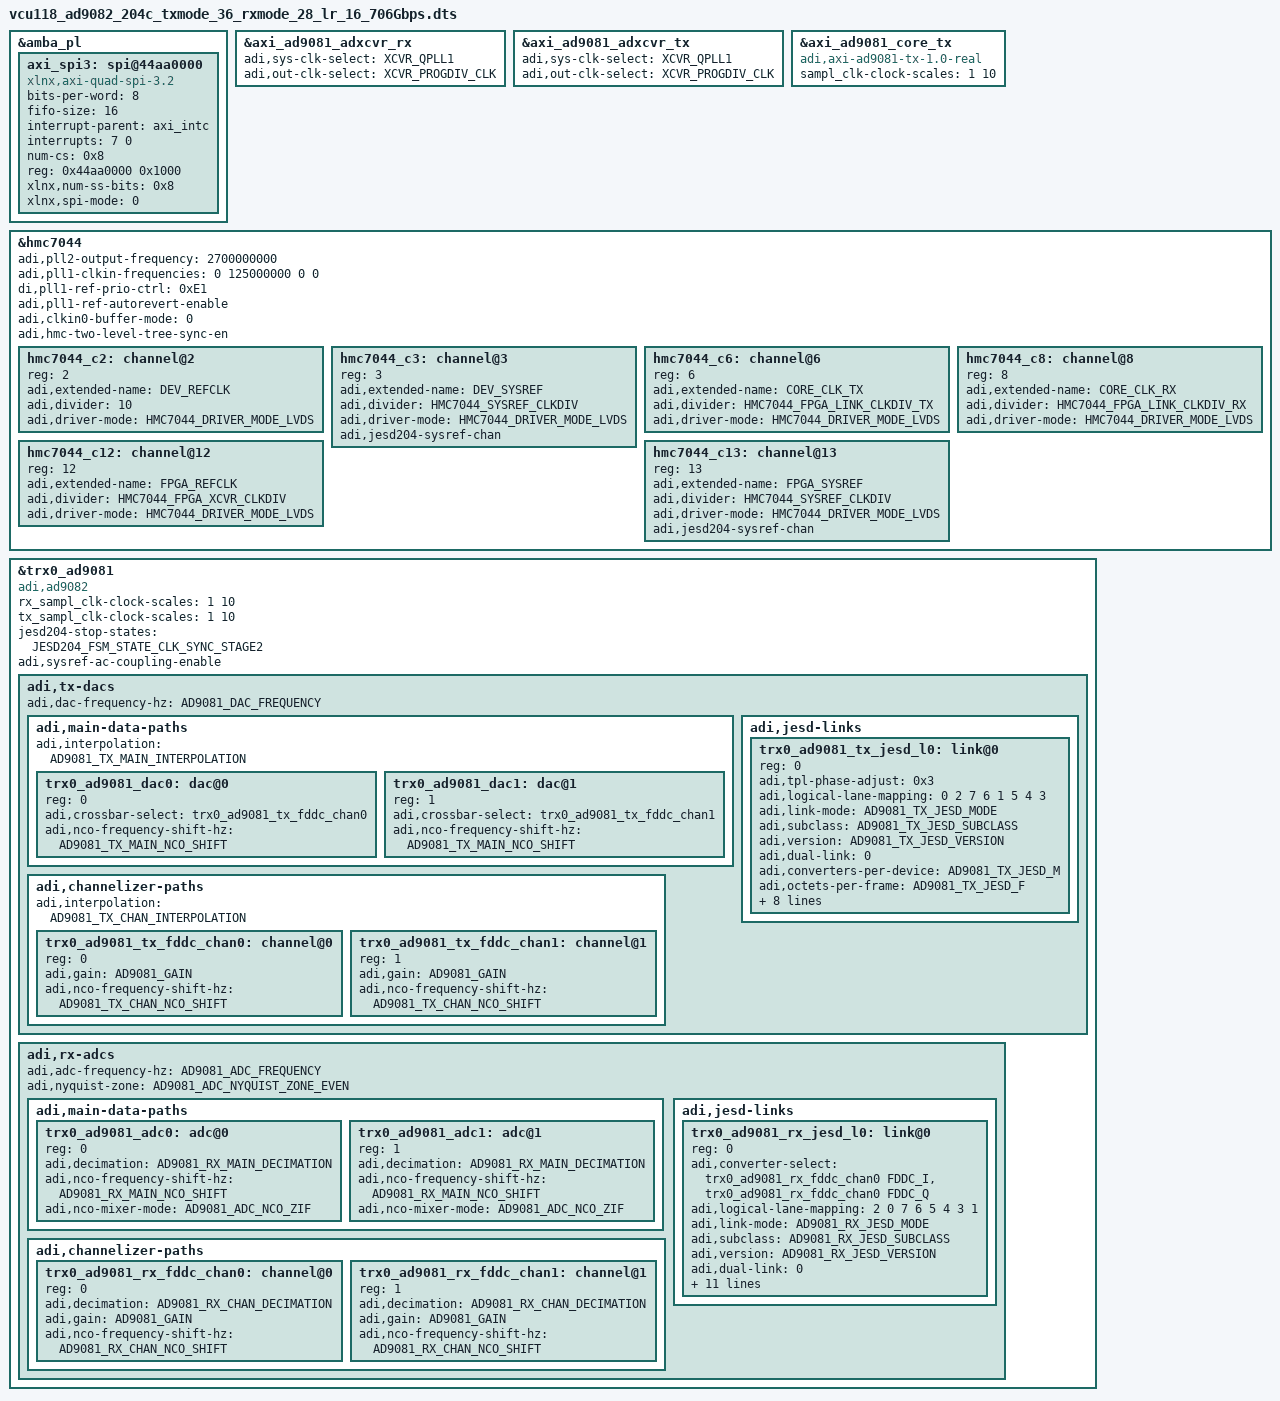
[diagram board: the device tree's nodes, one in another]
// SPDX-License-Identifier: GPL-2.0
/*
 * Analog Devices AD9082-FMC-EBZ
 * https://wiki.analog.com/resources/tools-software/linux-drivers/iio-mxfe/ad9081
 * https://wiki.analog.com/resources/eval/user-guides/ad9081_fmca_ebz/ad9081_fmca_ebz_hdl
 *
 * hdl_project: <ad9081_fmca_ebz/vcu118>
 * board_revision: <>
 *
 * Copyright (C) 2022 Analog Devices Inc.
 */

#include "vcu118_ad9081.dts"
#include <dt-bindings/jesd204/device-states.h>

#define HMC7044_FPGA_XCVR_CLKDIV		16
#define HMC7044_FPGA_LINK_CLKDIV_TX		16
#define HMC7044_FPGA_LINK_CLKDIV_RX		16
#define HMC7044_SYSREF_CLKDIV			256

/* TX path */
#define AD9081_DAC_FREQUENCY			5400000000
#define AD9081_TX_MAIN_INTERPOLATION		1
#define AD9081_TX_CHAN_INTERPOLATION		1
#define AD9081_TX_MAIN_NCO_SHIFT		0
#define AD9081_TX_CHAN_NCO_SHIFT		0

#define AD9081_GAIN				1024

#define AD9081_TX_JESD_MODE			36
#define AD9081_TX_JESD_SUBCLASS			1
#define AD9081_TX_JESD_VERSION			2
#define AD9081_TX_JESD_M			2
#define AD9081_TX_JESD_F			3
#define AD9081_TX_JESD_K			256
#define AD9081_TX_JESD_N			12
#define AD9081_TX_JESD_NP			12
#define AD9081_TX_JESD_CS			0
#define AD9081_TX_JESD_L			8
#define AD9081_TX_JESD_S			8
#define AD9081_TX_JESD_HD			1

#define AD9081_JRX_TPL_PHASE_ADJUST		15

/* RX path */
#define AD9081_ADC_FREQUENCY			5400000000
#define AD9081_RX_MAIN_DECIMATION		1
#define AD9081_RX_CHAN_DECIMATION		1
#define AD9081_RX_MAIN_NCO_SHIFT		0
#define AD9081_RX_CHAN_NCO_SHIFT		0

#define AD9081_RX_JESD_MODE			28
#define AD9081_RX_JESD_SUBCLASS			1
#define AD9081_RX_JESD_VERSION			2
#define AD9081_RX_JESD_M			2
#define AD9081_RX_JESD_F			3
#define AD9081_RX_JESD_K			256
#define AD9081_RX_JESD_N			12
#define AD9081_RX_JESD_NP			12
#define AD9081_RX_JESD_CS			0
#define AD9081_RX_JESD_L			8
#define AD9081_RX_JESD_S			8
#define AD9081_RX_JESD_HD			0

&amba_pl {
	axi_spi3: spi@44aa0000 {
		#address-cells = <1>;
		#size-cells = <0>;
		bits-per-word = <8>;
		compatible = "xlnx,axi-quad-spi-3.2", "xlnx,xps-spi-2.00.a";
		fifo-size = <16>;
		interrupt-names = "ip2intc_irpt";
		interrupt-parent = <&axi_intc>;
		interrupts = <7 0>;
		num-cs = <0x8>;
		reg = <0x44aa0000 0x1000>;
		xlnx,num-ss-bits = <0x8>;
		xlnx,spi-mode = <0>;
	};
};

&axi_ad9081_adxcvr_rx {
	adi,sys-clk-select = <XCVR_QPLL1>;
	adi,out-clk-select = <XCVR_PROGDIV_CLK>;
};

&axi_ad9081_adxcvr_tx {
	adi,sys-clk-select = <XCVR_QPLL1>;
	adi,out-clk-select = <XCVR_PROGDIV_CLK>;
};

&axi_ad9081_core_tx {
	compatible = "adi,axi-ad9081-tx-1.0-real";
	sampl_clk-clock-scales = <1 10>;
};

&hmc7044 {

		adi,pll2-output-frequency = <2700000000>; /* 3037500000*/
		adi,pll1-clkin-frequencies = <0 125000000 0 0>;

		di,pll1-ref-prio-ctrl = <0xE1>; /* prefer CLKIN1 -> CLKIN0 -> CLKIN2 -> CLKIN3 */
		adi,pll1-ref-autorevert-enable;
		adi,clkin0-buffer-mode = <0>;

		/delete-property/ adi,pfd1-maximum-limit-frequency-hz;

		/delete-property/ jesd204-sysref-provider;


		/delete-property/ adi,jesd204-max-sysref-frequency-hz;

		adi,hmc-two-level-tree-sync-en;

		hmc7044_c2: channel@2 {
			reg = <2>;
			adi,extended-name = "DEV_REFCLK";
			adi,divider = <10>;	// 600
			adi,driver-mode = <HMC7044_DRIVER_MODE_LVDS>;	// LVDS
		};

		hmc7044_c3: channel@3 {
			reg = <3>;
			adi,extended-name = "DEV_SYSREF";
			adi,divider = <HMC7044_SYSREF_CLKDIV>;	//
			adi,driver-mode = <HMC7044_DRIVER_MODE_LVDS>;	// LVDS
			adi,jesd204-sysref-chan;
			//adi,startup-mode-dynamic-enable;
		};

		hmc7044_c6: channel@6 {
			reg = <6>;
			adi,extended-name = "CORE_CLK_TX";
			adi,divider = <HMC7044_FPGA_LINK_CLKDIV_TX>;	// 375
			adi,driver-mode = <HMC7044_DRIVER_MODE_LVDS>;	// LVDS
		};

		hmc7044_c8: channel@8 {
			reg = <8>;
			adi,extended-name = "CORE_CLK_RX";
			adi,divider = <HMC7044_FPGA_LINK_CLKDIV_RX>;	// 375
			adi,driver-mode = <HMC7044_DRIVER_MODE_LVDS>;	// LVDS
		};

		hmc7044_c12: channel@12 {
			reg = <12>;
			adi,extended-name = "FPGA_REFCLK";
			adi,divider = <HMC7044_FPGA_XCVR_CLKDIV>;	// 375
			adi,driver-mode = <HMC7044_DRIVER_MODE_LVDS>;	// LVDS
		};

		hmc7044_c13: channel@13 {
			reg = <13>;
			adi,extended-name = "FPGA_SYSREF";
			adi,divider = <HMC7044_SYSREF_CLKDIV>;	//
			adi,driver-mode = <HMC7044_DRIVER_MODE_LVDS>;	// LVDS
			adi,jesd204-sysref-chan;
		};
};

&trx0_ad9081 {
	compatible = "adi,ad9082";

	rx_sampl_clk-clock-scales = <1 10>;
	tx_sampl_clk-clock-scales = <1 10>;

	jesd204-stop-states = <JESD204_FSM_STATE_CLK_SYNC_STAGE2>;

	adi,sysref-ac-coupling-enable;

	/delete-node/ adi,tx-dacs;
	/delete-node/ adi,rx-adcs;

	adi,tx-dacs {
		#size-cells = <0>;
		#address-cells = <1>;
		adi,dac-frequency-hz = /bits/ 64 <AD9081_DAC_FREQUENCY>;

		adi,main-data-paths {
			#address-cells = <1>;
			#size-cells = <0>;
			adi,interpolation = <AD9081_TX_MAIN_INTERPOLATION>;
			trx0_ad9081_dac0: dac@0 {
			    reg = <0>;
			    adi,crossbar-select = <&trx0_ad9081_tx_fddc_chan0>;
			    adi,nco-frequency-shift-hz = /bits/ 64 <AD9081_TX_MAIN_NCO_SHIFT>; /* 100 MHz */
			};
			trx0_ad9081_dac1: dac@1 {
			    reg = <1>;
			    adi,crossbar-select = <&trx0_ad9081_tx_fddc_chan1>;
			    adi,nco-frequency-shift-hz = /bits/ 64 <AD9081_TX_MAIN_NCO_SHIFT>; /* 100 MHz */
			};
		};

		adi,channelizer-paths {
			#address-cells = <1>;
			#size-cells = <0>;
			adi,interpolation = <AD9081_TX_CHAN_INTERPOLATION>;
			trx0_ad9081_tx_fddc_chan0: channel@0 {
			    reg = <0>;
			    adi,gain = <AD9081_GAIN>; /* value * 10^(gain_dB/20) */
			    adi,nco-frequency-shift-hz =  /bits/ 64 <AD9081_TX_CHAN_NCO_SHIFT>;
			};
			trx0_ad9081_tx_fddc_chan1: channel@1 {
			    reg = <1>;
			    adi,gain = <AD9081_GAIN>; /* value * 10^(gain_dB/20) */
			    adi,nco-frequency-shift-hz =  /bits/ 64 <AD9081_TX_CHAN_NCO_SHIFT>;
			};
		};

		adi,jesd-links {
			#size-cells = <0>;
			#address-cells = <1>;
			trx0_ad9081_tx_jesd_l0: link@0 {
				#address-cells = <1>;
				#size-cells = <0>;
				reg = <0>;
				adi,tpl-phase-adjust = <AD9081_JRX_TPL_PHASE_ADJUST>;
				adi,logical-lane-mapping = /bits/ 8 <0 2 7 6 1 5 4 3>;
				adi,link-mode = <AD9081_TX_JESD_MODE>;			/* JESD Quick Configuration Mode */
				adi,subclass = <AD9081_TX_JESD_SUBCLASS>;			/* JESD SUBCLASS 0,1,2 */
				adi,version = <AD9081_TX_JESD_VERSION>;			/* JESD VERSION 0=204A,1=204B,2=204C */
				adi,dual-link = <0>;			/* JESD Dual Link Mode */
				adi,converters-per-device = <AD9081_TX_JESD_M>;	/* JESD M */
				adi,octets-per-frame = <AD9081_TX_JESD_F>;		/* JESD F */
				adi,frames-per-multiframe = <AD9081_TX_JESD_K>;	/* JESD K */
				adi,converter-resolution = <AD9081_TX_JESD_N>;	/* JESD N */
				adi,bits-per-sample = <AD9081_TX_JESD_N>;		/* JESD NP' */
				adi,control-bits-per-sample = <AD9081_TX_JESD_CS>;	/* JESD CS */
				adi,lanes-per-device = <AD9081_TX_JESD_L>;		/* JESD L */
				adi,samples-per-converter-per-frame = <AD9081_TX_JESD_S>; /* JESD S */
				adi,high-density = <AD9081_TX_JESD_HD>;			/* JESD HD */

				adi,tpl-phase-adjust = <0x3>;
			};
		};
	};

	adi,rx-adcs {
		#size-cells = <0>;
		#address-cells = <1>;
		adi,adc-frequency-hz = /bits/ 64 <AD9081_ADC_FREQUENCY>;
		adi,nyquist-zone = <AD9081_ADC_NYQUIST_ZONE_EVEN>;
		adi,main-data-paths {
			#address-cells = <1>;
			#size-cells = <0>;
			trx0_ad9081_adc0: adc@0 {
				reg = <0>;
				adi,decimation = <AD9081_RX_MAIN_DECIMATION>;
				adi,nco-frequency-shift-hz =  /bits/ 64 <AD9081_RX_MAIN_NCO_SHIFT>;
				adi,nco-mixer-mode = <AD9081_ADC_NCO_ZIF>;
				//adi,crossbar-select = <&trx0_ad9081_rx_fddc_chan0>, <&trx0_ad9081_rx_fddc_chan2>; /* Static for now */
			};
			trx0_ad9081_adc1: adc@1 {
				reg = <1>;
				adi,decimation = <AD9081_RX_MAIN_DECIMATION>;
				adi,nco-frequency-shift-hz =  /bits/ 64 <AD9081_RX_MAIN_NCO_SHIFT>;
				adi,nco-mixer-mode = <AD9081_ADC_NCO_ZIF>;
				//adi,crossbar-select = <&trx0_ad9081_rx_fddc_chan0>, <&trx0_ad9081_rx_fddc_chan2>; /* Static for now */
			};
		};
		adi,channelizer-paths {
			#address-cells = <1>;
			#size-cells = <0>;
			trx0_ad9081_rx_fddc_chan0: channel@0 {
				reg = <0>;
				adi,decimation = <AD9081_RX_CHAN_DECIMATION>;
				adi,gain = <AD9081_GAIN>; /* value * 10^(gain_dB/20) */
				adi,nco-frequency-shift-hz =  /bits/ 64 <AD9081_RX_CHAN_NCO_SHIFT>;
			};
			trx0_ad9081_rx_fddc_chan1: channel@1 {
				reg = <1>;
				adi,decimation = <AD9081_RX_CHAN_DECIMATION>;
				adi,gain = <AD9081_GAIN>; /* value * 10^(gain_dB/20) */
				adi,nco-frequency-shift-hz =  /bits/ 64 <AD9081_RX_CHAN_NCO_SHIFT>;
			};
		};
		adi,jesd-links {
			#size-cells = <0>;
			#address-cells = <1>;
			trx0_ad9081_rx_jesd_l0: link@0 {
				reg = <0>;
				adi,converter-select =
					<&trx0_ad9081_rx_fddc_chan0 FDDC_I>, <&trx0_ad9081_rx_fddc_chan0 FDDC_Q>;

				adi,logical-lane-mapping = /bits/ 8 <2 0 7 6 5 4 3 1>;
				adi,link-mode = <AD9081_RX_JESD_MODE>;			/* JESD Quick Configuration Mode */
				adi,subclass = <AD9081_RX_JESD_SUBCLASS>;			/* JESD SUBCLASS 0,1,2 */
				adi,version = <AD9081_RX_JESD_VERSION>;			/* JESD VERSION 0=204A,1=204B,2=204C */
				adi,dual-link = <0>;			/* JESD Dual Link Mode */
				adi,device-id = <3>;
				adi,converters-per-device = <AD9081_RX_JESD_M>;	/* JESD M */
				adi,octets-per-frame = <AD9081_RX_JESD_F>;		/* JESD F */
				adi,frames-per-multiframe = <AD9081_RX_JESD_K>;	/* JESD K */
				adi,converter-resolution = <AD9081_RX_JESD_N>;	/* JESD N */
				adi,bits-per-sample = <AD9081_RX_JESD_NP>;		/* JESD NP' */
				adi,control-bits-per-sample = <AD9081_RX_JESD_CS>;	/* JESD CS */
				adi,lanes-per-device = <AD9081_RX_JESD_L>;		/* JESD L */
				adi,samples-per-converter-per-frame = <AD9081_RX_JESD_S>; /* JESD S */
				adi,high-density = <AD9081_RX_JESD_HD>;			/* JESD HD */
			};
		};
	};


};

#if 0
&axi_spi3 {
	hmc7044_ext_synchrona: hmc7044-ext@0 {
		#address-cells = <1>;
		#size-cells = <0>;
		#clock-cells = <1>;
		compatible = "adi,hmc7044";
		reg = <0>;
		spi-max-frequency = <100000>;

		adi,vcxo-frequency = <100000000>;

		adi,clkin0-buffer-mode = <HMC7044_CLKIN_AC_COUPLING>;
		adi,clkin1-buffer-mode = <HMC7044_CLKIN_AC_COUPLING>;
		adi,clkin2-buffer-mode = <HMC7044_CLKIN_AC_COUPLING>;
		adi,clkin3-buffer-mode = <HMC7044_CLKIN_AC_COUPLING>;
		adi,oscin-buffer-mode = <0x15>;

		adi,pll1-clkin-frequencies =
			<40000000 40000000 40000000 40000000>;

		/* CLKIN0 -> CLKIN1 -> CLKIN2 -> CLKIN3 */
		adi,pll1-ref-prio-ctrl = <0xE4>;
		adi,pll1-ref-autorevert-enable;
		adi,pll1-loop-bandwidth-hz = <200>;
		adi,pfd1-maximum-limit-frequency-hz = <3840000>;

		adi,pll2-output-frequency = <3000000000>;

		adi,pulse-generator-mode = <HMC7044_PULSE_GEN_1_PULSE>;
		adi,sync-pin-mode = <HMC7044_SYNC_PIN_DISABLED>;

		adi,gpi-controls = <0x00 0x00 0x00 0x00>;
		adi,gpo-controls = <0x1f 0x2b 0x00 0x00>;

		/* JESD204-FSM */
		jesd204-device;
		#jesd204-cells = <2>;
		jesd204-sysref-provider;
		adi,hmc-two-level-tree-sync-en;
		adi,jesd204-max-sysref-frequency-hz = <2000000>;

		clock-output-names =
			"hmc7044_e_out0", "hmc7044_e_out1",
			"hmc7044_e_out2", "hmc7044_e_out3",
			"hmc7044_e_out4", "hmc7044_e_out5",
			"hmc7044_e_out6_RFSYNC_A", "hmc7044_e_out7_REFCLK_A",
			"hmc7044_e_out8","hmc7044_e_out9",
			"hmc7044_e_out10_REFCLK_B", "hmc7044_e_out11_RFSYNC_B",
			"hmc7044_e_out12", "hmc7044_e_out13";

		hmc7044_ext_c6: channel@6 {
			reg = <6>;
			adi,extended-name = "RFSYNC_A";
			adi,divider = <1024>; /* set by the jesd204-fsm */
			adi,driver-mode = <HMC7044_DRIVER_MODE_LVPECL>;
			adi,driver-impedance-mode =
				<HMC7044_DRIVER_IMPEDANCE_100_OHM>;
			adi,startup-mode-dynamic-enable;
			adi,high-performance-mode-disable;
			adi,force-mute-enable;
		};

		hmc7044_ext_c7: channel@7 {
			reg = <7>;
			adi,extended-name = "REFCLK_A";
			adi,divider = <6>;
			adi,driver-mode = <HMC7044_DRIVER_MODE_LVDS>;
		};

		hmc7044_ext_c10: channel@10 {
			reg = <10>;
			adi,extended-name = "REFCLK_B";
			adi,divider = <6>;
			adi,driver-mode = <HMC7044_DRIVER_MODE_LVDS>;
		};

		hmc7044_ext_c11: channel@11 {
			reg = <11>;
			adi,extended-name = "RFSYNC_B";
			adi,divider = <1024>; /* set by the jesd204-fsm */
			adi,driver-mode = <HMC7044_DRIVER_MODE_LVPECL>;
			adi,driver-impedance-mode =
				<HMC7044_DRIVER_IMPEDANCE_100_OHM>;
			adi,startup-mode-dynamic-enable;
			adi,high-performance-mode-disable;
			adi,force-mute-enable;
		};
	};
};
#endif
